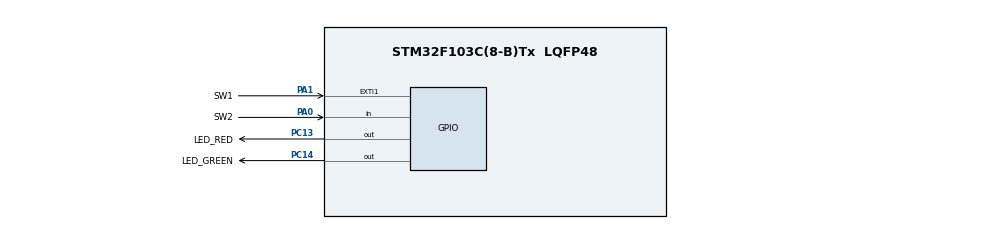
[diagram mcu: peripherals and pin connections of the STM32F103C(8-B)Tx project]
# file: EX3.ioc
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Mcu.Family=STM32F1
Mcu.Name=STM32F103C(8-B)Tx
Mcu.Package=LQFP48
NVIC.EXTI1_IRQn=true\:0\:0\:false\:false\:true\:true\:true\:true
NVIC.PriorityGroup=NVIC_PRIORITYGROUP_4
PA0-WKUP.GPIO_Label=SW2
PA0-WKUP.GPIO_PuPd=GPIO_PULLUP
PA0-WKUP.Signal=GPIO_Input
PA1.GPIO_Label=SW1
PA1.Signal=GPXTI1
PA13.Mode=Serial_Wire
PA13.Signal=SYS_JTMS-SWDIO
PA14.Mode=Serial_Wire
PA14.Signal=SYS_JTCK-SWCLK
PC13-TAMPER-RTC.GPIO_Label=LED_RED
PC13-TAMPER-RTC.Signal=GPIO_Output
PC14-OSC32_IN.GPIO_Label=LED_GREEN
PC14-OSC32_IN.Signal=GPIO_Output
ProjectManager.HeapSize=0x200
ProjectManager.StackSize=0x400
ProjectManager.TargetToolchain=MDK-ARM V5.32
RCC.APB1Freq_Value=8000000
RCC.APB2Freq_Value=8000000
board=custom

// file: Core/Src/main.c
/* USER CODE BEGIN Header */
/**
  ******************************************************************************
  * @file           : main.c
  * @brief          : Main program body
  ******************************************************************************
  * @attention
  *
  * Copyright (c) 2023 STMicroelectronics.
  * All rights reserved.
  *
  * This software is licensed under terms that can be found in the LICENSE file
  * in the root directory of this software component.
  * If no LICENSE file comes with this software, it is provided AS-IS.
  *
  ******************************************************************************
  */
/* USER CODE END Header */
#include "main.h"

// Global variables
volatile int flag=0;
volatile uint8_t red_led_state = 0;
volatile uint8_t green_led_state = 0;

void SystemClock_Config(void);
static void MX_GPIO_Init(void);

/* USER CODE BEGIN 0 */
uint8_t FLAG = 0;
/* USER CODE END 0 */
int main(void)
{
	HAL_Init();
	SystemClock_Config();
	MX_GPIO_Init();
	while(1){
	if(HAL_GPIO_ReadPin(SW2_GPIO_Port,SW2_Pin) == RESET)
  {
    while(HAL_GPIO_ReadPin(SW2_GPIO_Port,SW2_Pin) == RESET);
		FLAG =~FLAG;
		HAL_GPIO_WritePin(LED_GREEN_GPIO_Port,LED_GREEN_Pin,FLAG);
	}
	}
}
void EXTI0_IRQHandler(void)
{
    // Clear the interrupt flag
    HAL_GPIO_EXTI_IRQHandler(SW1_Pin);

    // Toggle the state of the RED LED

}
void HAL_GPIO_EXTI_Callback(uint16_t GPIO_Pin)
{
	if(GPIO_Pin==GPIO_PIN_0)
	{
		HAL_GPIO_WritePin(LED_RED_GPIO_Port,LED_RED_Pin,GPIO_PIN_RESET);
	}
}

void SystemClock_Config(void)
{
  RCC_OscInitTypeDef RCC_OscInitStruct = {0};
  RCC_ClkInitTypeDef RCC_ClkInitStruct = {0};

  /** Initializes the RCC Oscillators according to the specified parameters
  * in the RCC_OscInitTypeDef structure.
  */
  RCC_OscInitStruct.OscillatorType = RCC_OSCILLATORTYPE_HSI;
  RCC_OscInitStruct.HSIState = RCC_HSI_ON;
  RCC_OscInitStruct.HSICalibrationValue = RCC_HSICALIBRATION_DEFAULT;
  RCC_OscInitStruct.PLL.PLLState = RCC_PLL_NONE;
  if (HAL_RCC_OscConfig(&RCC_OscInitStruct) != HAL_OK)
  {
    Error_Handler();
  }

  /** Initializes the CPU, AHB and APB buses clocks
  */
  RCC_ClkInitStruct.ClockType = RCC_CLOCKTYPE_HCLK|RCC_CLOCKTYPE_SYSCLK
                              |RCC_CLOCKTYPE_PCLK1|RCC_CLOCKTYPE_PCLK2;
  RCC_ClkInitStruct.SYSCLKSource = RCC_SYSCLKSOURCE_HSI;
  RCC_ClkInitStruct.AHBCLKDivider = RCC_SYSCLK_DIV1;
  RCC_ClkInitStruct.APB1CLKDivider = RCC_HCLK_DIV1;
  RCC_ClkInitStruct.APB2CLKDivider = RCC_HCLK_DIV1;

  if (HAL_RCC_ClockConfig(&RCC_ClkInitStruct, FLASH_LATENCY_0) != HAL_OK)
  {
    Error_Handler();
  }
}

static void MX_GPIO_Init(void)
{
  GPIO_InitTypeDef GPIO_InitStruct = {0};

  /* GPIO Ports Clock Enable */
  __HAL_RCC_GPIOC_CLK_ENABLE();
  __HAL_RCC_GPIOA_CLK_ENABLE();

  /*Configure GPIO pin Output Level */
  HAL_GPIO_WritePin(GPIOC, LED_RED_Pin|LED_GREEN_Pin, GPIO_PIN_RESET);

  /*Configure GPIO pins : LED_RED_Pin LED_GREEN_Pin */
  GPIO_InitStruct.Pin = LED_RED_Pin|LED_GREEN_Pin;
  GPIO_InitStruct.Mode = GPIO_MODE_OUTPUT_PP;
  GPIO_InitStruct.Pull = GPIO_NOPULL;
  GPIO_InitStruct.Speed = GPIO_SPEED_FREQ_LOW;
  HAL_GPIO_Init(GPIOC, &GPIO_InitStruct);

  /*Configure GPIO pin : SW2_Pin */
  GPIO_InitStruct.Pin = SW2_Pin;
  GPIO_InitStruct.Mode = GPIO_MODE_INPUT;
  GPIO_InitStruct.Pull = GPIO_PULLUP;
  HAL_GPIO_Init(SW2_GPIO_Port, &GPIO_InitStruct);

  /*Configure GPIO pin : SW1_Pin */
  GPIO_InitStruct.Pin = SW1_Pin;
  GPIO_InitStruct.Mode = GPIO_MODE_IT_RISING;
  GPIO_InitStruct.Pull = GPIO_NOPULL;
  HAL_GPIO_Init(SW1_GPIO_Port, &GPIO_InitStruct);

  /* EXTI interrupt init*/
  HAL_NVIC_SetPriority(EXTI1_IRQn, 0, 0);
  HAL_NVIC_EnableIRQ(EXTI1_IRQn);

}

void Error_Handler(void)
{
  __disable_irq();
  while (1)
  {
  }
}
